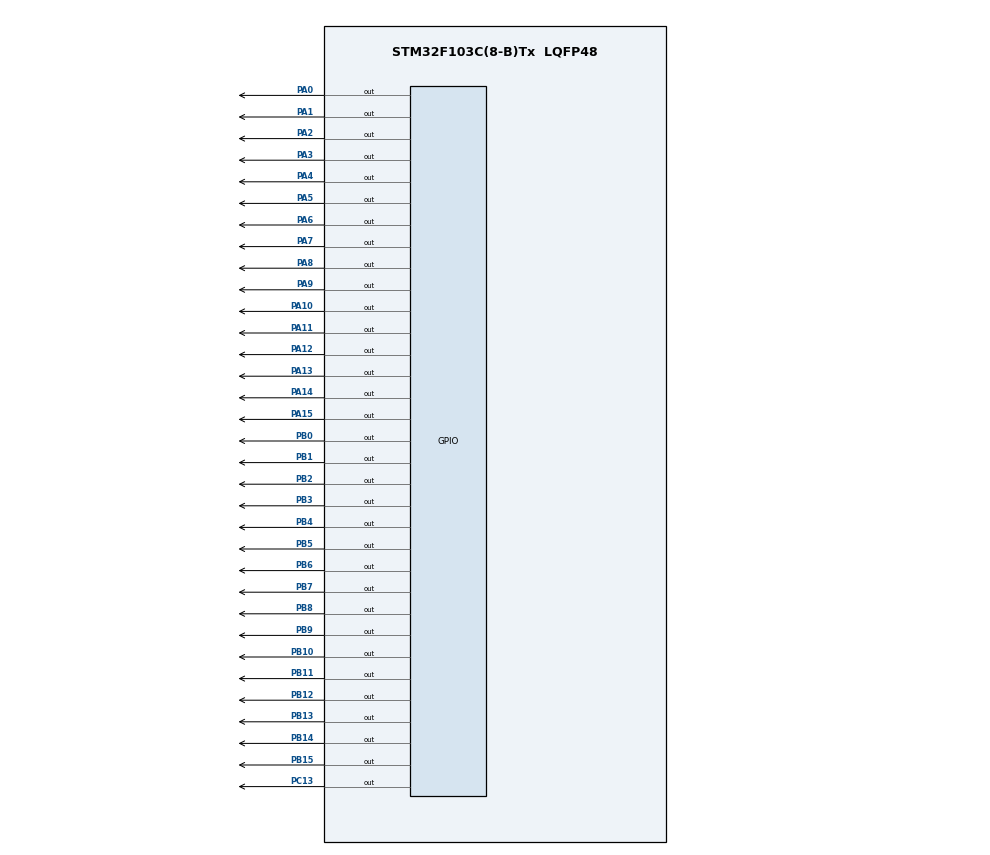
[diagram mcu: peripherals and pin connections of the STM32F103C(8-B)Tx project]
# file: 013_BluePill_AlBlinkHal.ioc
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Mcu.Family=STM32F1
PC15-OSC32_OUT.Mode=LSE-External-Oscillator
PD1-OSC_OUT.Mode=HSE-External-Oscillator
PC13-TAMPER-RTC.Signal=GPIO_Output
PD0-OSC_IN.Signal=RCC_OSC_IN
PC14-OSC32_IN.Signal=RCC_OSC32_IN
PB11.Signal=GPIO_Output
PB15.Signal=GPIO_Output
PB13.Signal=GPIO_Output
VP_SYS_VS_ND.Mode=No_Debug
ProjectManager.StackSize=0x400
PA0-WKUP.Signal=GPIO_Output
PD1-OSC_OUT.Signal=RCC_OSC_OUT
PA13.Signal=GPIO_Output
PA12.Signal=GPIO_Output
ProjectManager.TargetToolchain=STM32CubeIDE
PA9.Signal=GPIO_Output
PB6.Signal=GPIO_Output
PC15-OSC32_OUT.Signal=RCC_OSC32_OUT
PA1.Signal=GPIO_Output
PD0-OSC_IN.Mode=HSE-External-Oscillator
PB10.Signal=GPIO_Output
PB14.Signal=GPIO_Output
PA5.Signal=GPIO_Output
PB2.Signal=GPIO_Output
board=custom
RCC.APB2Freq_Value=8000000
PC14-OSC32_IN.Mode=LSE-External-Oscillator
PB7.Signal=GPIO_Output
PA8.Signal=GPIO_Output
Mcu.Name=STM32F103C(8-B)Tx
PA2.Signal=GPIO_Output
PB3.Signal=GPIO_Output
PA4.Signal=GPIO_Output
Mcu.Package=LQFP48
PB5.Signal=GPIO_Output
PB9.Signal=GPIO_Output
PB1.Signal=GPIO_Output
PA6.Signal=GPIO_Output
PA11.Signal=GPIO_Output
PA10.Signal=GPIO_Output
PA14.Signal=GPIO_Output
PA15.Signal=GPIO_Output
ProjectManager.HeapSize=0x200
NVIC.PriorityGroup=NVIC_PRIORITYGROUP_4
PB8.Signal=GPIO_Output
RCC.APB1Freq_Value=8000000
PB0.Signal=GPIO_Output
PB12.Signal=GPIO_Output
PB4.Signal=GPIO_Output
PA3.Signal=GPIO_Output
PA7.Signal=GPIO_Output

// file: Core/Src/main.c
/* USER CODE BEGIN Header */
/**
  ******************************************************************************
  * @file           : main.c
  * @brief          : Main program body
  ******************************************************************************
  * @attention
  *
  * <h2><center>&copy; Copyright (c) 2021 STMicroelectronics.
  * All rights reserved.</center></h2>
  *
  * This software component is licensed by ST under BSD 3-Clause license,
  * the "License"; You may not use this file except in compliance with the
  * License. You may obtain a copy of the License at:
  *                        opensource.org/licenses/BSD-3-Clause
  *
  ******************************************************************************
  */
/* USER CODE END Header */
#include "main.h"

void SystemClock_Config(void);
static void MX_GPIO_Init(void);

int main(void)
{

  /* MCU Configuration--------------------------------------------------------*/

  /* Reset of all peripherals, Initializes the Flash interface and the Systick. */
  HAL_Init();

  /* Configure the system clock */
  SystemClock_Config();

  /* Initialize all configured peripherals */
  MX_GPIO_Init();

  /* Infinite loop */
  /* USER CODE BEGIN WHILE */
  while (1)
  {
	  HAl_GPIO_TogglePin(GPIOC, GPIO_PIN13);
	  HAL_Dela(100);
    /* USER CODE END WHILE */

  }
}

void SystemClock_Config(void)
{
  RCC_OscInitTypeDef RCC_OscInitStruct = {0};
  RCC_ClkInitTypeDef RCC_ClkInitStruct = {0};

  /** Initializes the RCC Oscillators according to the specified parameters
  * in the RCC_OscInitTypeDef structure.
  */
  RCC_OscInitStruct.OscillatorType = RCC_OSCILLATORTYPE_HSI;
  RCC_OscInitStruct.HSIState = RCC_HSI_ON;
  RCC_OscInitStruct.HSICalibrationValue = RCC_HSICALIBRATION_DEFAULT;
  RCC_OscInitStruct.PLL.PLLState = RCC_PLL_NONE;
  if (HAL_RCC_OscConfig(&RCC_OscInitStruct) != HAL_OK)
  {
    Error_Handler();
  }
  /** Initializes the CPU, AHB and APB buses clocks
  */
  RCC_ClkInitStruct.ClockType = RCC_CLOCKTYPE_HCLK|RCC_CLOCKTYPE_SYSCLK
                              |RCC_CLOCKTYPE_PCLK1|RCC_CLOCKTYPE_PCLK2;
  RCC_ClkInitStruct.SYSCLKSource = RCC_SYSCLKSOURCE_HSI;
  RCC_ClkInitStruct.AHBCLKDivider = RCC_SYSCLK_DIV1;
  RCC_ClkInitStruct.APB1CLKDivider = RCC_HCLK_DIV1;
  RCC_ClkInitStruct.APB2CLKDivider = RCC_HCLK_DIV1;

  if (HAL_RCC_ClockConfig(&RCC_ClkInitStruct, FLASH_LATENCY_0) != HAL_OK)
  {
    Error_Handler();
  }
}

static void MX_GPIO_Init(void)
{
  GPIO_InitTypeDef GPIO_InitStruct = {0};

  /* GPIO Ports Clock Enable */
  __HAL_RCC_GPIOC_CLK_ENABLE();
  __HAL_RCC_GPIOD_CLK_ENABLE();
  __HAL_RCC_GPIOA_CLK_ENABLE();
  __HAL_RCC_GPIOB_CLK_ENABLE();

  /*Configure GPIO pin Output Level */
  HAL_GPIO_WritePin(GPIOC, GPIO_PIN_13, GPIO_PIN_RESET);

  /*Configure GPIO pin Output Level */
  HAL_GPIO_WritePin(GPIOA, GPIO_PIN_0|GPIO_PIN_1|GPIO_PIN_2|GPIO_PIN_3
                          |GPIO_PIN_4|GPIO_PIN_5|GPIO_PIN_6|GPIO_PIN_7
                          |GPIO_PIN_8|GPIO_PIN_9|GPIO_PIN_10|GPIO_PIN_11
                          |GPIO_PIN_12|GPIO_PIN_13|GPIO_PIN_14|GPIO_PIN_15, GPIO_PIN_RESET);

  /*Configure GPIO pin Output Level */
  HAL_GPIO_WritePin(GPIOB, GPIO_PIN_0|GPIO_PIN_1|GPIO_PIN_2|GPIO_PIN_10
                          |GPIO_PIN_11|GPIO_PIN_12|GPIO_PIN_13|GPIO_PIN_14
                          |GPIO_PIN_15|GPIO_PIN_3|GPIO_PIN_4|GPIO_PIN_5
                          |GPIO_PIN_6|GPIO_PIN_7|GPIO_PIN_8|GPIO_PIN_9, GPIO_PIN_RESET);

  /*Configure GPIO pin : PC13 */
  GPIO_InitStruct.Pin = GPIO_PIN_13;
  GPIO_InitStruct.Mode = GPIO_MODE_OUTPUT_PP;
  GPIO_InitStruct.Pull = GPIO_NOPULL;
  GPIO_InitStruct.Speed = GPIO_SPEED_FREQ_LOW;
  HAL_GPIO_Init(GPIOC, &GPIO_InitStruct);

  /*Configure GPIO pins : PA0 PA1 PA2 PA3
                           PA4 PA5 PA6 PA7
                           PA8 PA9 PA10 PA11
                           PA12 PA13 PA14 PA15 */
  GPIO_InitStruct.Pin = GPIO_PIN_0|GPIO_PIN_1|GPIO_PIN_2|GPIO_PIN_3
                          |GPIO_PIN_4|GPIO_PIN_5|GPIO_PIN_6|GPIO_PIN_7
                          |GPIO_PIN_8|GPIO_PIN_9|GPIO_PIN_10|GPIO_PIN_11
                          |GPIO_PIN_12|GPIO_PIN_13|GPIO_PIN_14|GPIO_PIN_15;
  GPIO_InitStruct.Mode = GPIO_MODE_OUTPUT_PP;
  GPIO_InitStruct.Pull = GPIO_NOPULL;
  GPIO_InitStruct.Speed = GPIO_SPEED_FREQ_LOW;
  HAL_GPIO_Init(GPIOA, &GPIO_InitStruct);

  /*Configure GPIO pins : PB0 PB1 PB2 PB10
                           PB11 PB12 PB13 PB14
                           PB15 PB3 PB4 PB5
                           PB6 PB7 PB8 PB9 */
  GPIO_InitStruct.Pin = GPIO_PIN_0|GPIO_PIN_1|GPIO_PIN_2|GPIO_PIN_10
                          |GPIO_PIN_11|GPIO_PIN_12|GPIO_PIN_13|GPIO_PIN_14
                          |GPIO_PIN_15|GPIO_PIN_3|GPIO_PIN_4|GPIO_PIN_5
                          |GPIO_PIN_6|GPIO_PIN_7|GPIO_PIN_8|GPIO_PIN_9;
  GPIO_InitStruct.Mode = GPIO_MODE_OUTPUT_PP;
  GPIO_InitStruct.Pull = GPIO_NOPULL;
  GPIO_InitStruct.Speed = GPIO_SPEED_FREQ_LOW;
  HAL_GPIO_Init(GPIOB, &GPIO_InitStruct);

}

void Error_Handler(void)
{
  __disable_irq();
  while (1)
  {
  }
}

/************************ (C) COPYRIGHT STMicroelectronics *****END OF FILE****/
